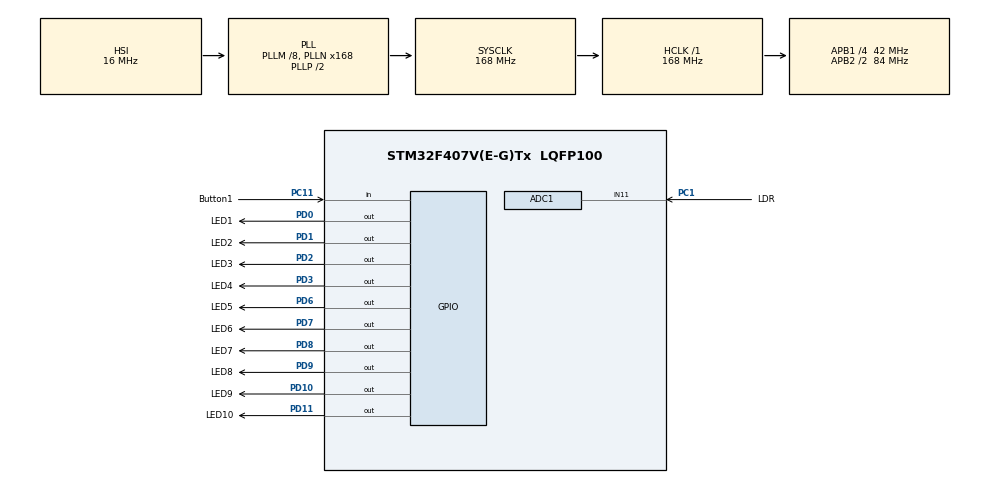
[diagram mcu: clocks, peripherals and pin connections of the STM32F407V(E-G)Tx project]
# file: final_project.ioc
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ADC1.Channel-0\#ChannelRegularConversion=ADC_CHANNEL_11
ADC1.ContinuousConvMode=ENABLE
ADC1.NbrOfConversionFlag=1
ADC1.Rank-0\#ChannelRegularConversion=1
ADC1.SamplingTime-0\#ChannelRegularConversion=ADC_SAMPLETIME_480CYCLES
ADC1.master=1
Mcu.Family=STM32F4
Mcu.Name=STM32F407V(E-G)Tx
Mcu.Package=LQFP100
NVIC.ADC_IRQn=true\:0\:0\:false\:false\:true\:true\:true\:true
NVIC.PriorityGroup=NVIC_PRIORITYGROUP_4
NVIC.TIM4_IRQn=true\:0\:0\:false\:false\:true\:true\:true\:true
PC1.GPIO_Label=LDR
PC1.Signal=ADCx_IN11
PC11.GPIO_Label=Button1
PC11.Signal=GPIO_Input
PD0.GPIO_Label=LED1
PD0.Signal=GPIO_Output
PD1.GPIO_Label=LED2
PD1.Signal=GPIO_Output
PD10.GPIO_Label=LED9
PD10.Signal=GPIO_Output
PD11.GPIO_Label=LED10
PD11.Signal=GPIO_Output
PD2.GPIO_Label=LED3
PD2.Signal=GPIO_Output
PD3.GPIO_Label=LED4
PD3.Signal=GPIO_Output
PD6.GPIO_Label=LED5
PD6.Signal=GPIO_Output
PD7.GPIO_Label=LED6
PD7.Signal=GPIO_Output
PD8.GPIO_Label=LED7
PD8.Signal=GPIO_Output
PD9.GPIO_Label=LED8
PD9.Signal=GPIO_Output
ProjectManager.HeapSize=0x200
ProjectManager.StackSize=0x400
ProjectManager.TargetToolchain=STM32CubeIDE
RCC.48MHZClocksFreq_Value=84000000
RCC.AHBFreq_Value=168000000
RCC.APB1CLKDivider=RCC_HCLK_DIV4
RCC.APB1Freq_Value=42000000
RCC.APB1TimFreq_Value=84000000
RCC.APB2CLKDivider=RCC_HCLK_DIV2
RCC.APB2Freq_Value=84000000
RCC.APB2TimFreq_Value=168000000
RCC.CortexFreq_Value=168000000
RCC.HCLKFreq_Value=168000000
RCC.HSE_VALUE=25000000
RCC.HSI_VALUE=16000000
RCC.LSE_VALUE=32768
RCC.PLLM=8
RCC.PLLN=168
RCC.SYSCLKFreq_VALUE=168000000
RCC.SYSCLKSource=RCC_SYSCLKSOURCE_PLLCLK
RCC.VCOOutputFreq_Value=336000000
SH.ADCx_IN11.0=ADC1_IN11,IN11
TIM4.Period=200
TIM4.Prescaler=42000-1
TIM9.Period=4096-1
TIM9.Prescaler=16800-1
VP_TIM4_VS_ClockSourceINT.Mode=Internal
VP_TIM9_VS_ClockSourceINT.Mode=Internal
board=custom

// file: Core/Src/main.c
/* USER CODE BEGIN Header */
/**
  ******************************************************************************
  * @file           : main.c
  * @brief          : Main program body
  ******************************************************************************
  * @attention
  *
  * Copyright (c) 2023 STMicroelectronics.
  * All rights reserved.
  *
  * This software is licensed under terms that can be found in the LICENSE file
  * in the root directory of this software component.
  * If no LICENSE file comes with this software, it is provided AS-IS.
  *
  ******************************************************************************
  */
/* USER CODE END Header */
#include "main.h"

/* USER CODE BEGIN Includes */

#include "arm_math.h"
arm_fir_instance_f32 myFilter;

//// CHECK SOFTWARE PACKS COMPONENT SELECTROR FOR FOR XCUBE ALGOBUILD - YOU WILL SEE DSP LIBRARY
//// ON THE IOC WINDOW YOU WILL SEE MIDDLEWARE - CHECK POSSIBILITIES

/* USER CODE END Includes */

ADC_HandleTypeDef hadc1;

TIM_HandleTypeDef htim4;
TIM_HandleTypeDef htim9;

void SystemClock_Config(void);
static void MX_GPIO_Init(void);
static void MX_ADC1_Init(void);
static void MX_TIM4_Init(void);
static void MX_TIM9_Init(void);

int main(void)
{

  /* MCU Configuration--------------------------------------------------------*/

  /* Reset of all peripherals, Initializes the Flash interface and the Systick. */
  HAL_Init();

  /* Configure the system clock */
  SystemClock_Config();

  /* Initialize all configured peripherals */
  MX_GPIO_Init();
  MX_ADC1_Init();
  MX_TIM4_Init();
  MX_TIM9_Init();

  /* Infinite loop */
  while (1)
  {

  }
}

void SystemClock_Config(void)
{
  RCC_OscInitTypeDef RCC_OscInitStruct = {0};
  RCC_ClkInitTypeDef RCC_ClkInitStruct = {0};

  /** Configure the main internal regulator output voltage
  */
  __HAL_RCC_PWR_CLK_ENABLE();
  __HAL_PWR_VOLTAGESCALING_CONFIG(PWR_REGULATOR_VOLTAGE_SCALE1);

  /** Initializes the RCC Oscillators according to the specified parameters
  * in the RCC_OscInitTypeDef structure.
  */
  RCC_OscInitStruct.OscillatorType = RCC_OSCILLATORTYPE_HSI;
  RCC_OscInitStruct.HSIState = RCC_HSI_ON;
  RCC_OscInitStruct.HSICalibrationValue = RCC_HSICALIBRATION_DEFAULT;
  RCC_OscInitStruct.PLL.PLLState = RCC_PLL_ON;
  RCC_OscInitStruct.PLL.PLLSource = RCC_PLLSOURCE_HSI;
  RCC_OscInitStruct.PLL.PLLM = 8;
  RCC_OscInitStruct.PLL.PLLN = 168;
  RCC_OscInitStruct.PLL.PLLP = RCC_PLLP_DIV2;
  RCC_OscInitStruct.PLL.PLLQ = 4;
  if (HAL_RCC_OscConfig(&RCC_OscInitStruct) != HAL_OK)
  {
    Error_Handler();
  }

  /** Initializes the CPU, AHB and APB buses clocks
  */
  RCC_ClkInitStruct.ClockType = RCC_CLOCKTYPE_HCLK|RCC_CLOCKTYPE_SYSCLK
                              |RCC_CLOCKTYPE_PCLK1|RCC_CLOCKTYPE_PCLK2;
  RCC_ClkInitStruct.SYSCLKSource = RCC_SYSCLKSOURCE_PLLCLK;
  RCC_ClkInitStruct.AHBCLKDivider = RCC_SYSCLK_DIV1;
  RCC_ClkInitStruct.APB1CLKDivider = RCC_HCLK_DIV4;
  RCC_ClkInitStruct.APB2CLKDivider = RCC_HCLK_DIV2;

  if (HAL_RCC_ClockConfig(&RCC_ClkInitStruct, FLASH_LATENCY_5) != HAL_OK)
  {
    Error_Handler();
  }
}

static void MX_ADC1_Init(void)
{

  ADC_ChannelConfTypeDef sConfig = {0};

  /** Configure the global features of the ADC (Clock, Resolution, Data Alignment and number of conversion)
  */
  hadc1.Instance = ADC1;
  hadc1.Init.ClockPrescaler = ADC_CLOCK_SYNC_PCLK_DIV4;
  hadc1.Init.Resolution = ADC_RESOLUTION_12B;
  hadc1.Init.ScanConvMode = DISABLE;
  hadc1.Init.ContinuousConvMode = ENABLE;
  hadc1.Init.DiscontinuousConvMode = DISABLE;
  hadc1.Init.ExternalTrigConvEdge = ADC_EXTERNALTRIGCONVEDGE_NONE;
  hadc1.Init.ExternalTrigConv = ADC_SOFTWARE_START;
  hadc1.Init.DataAlign = ADC_DATAALIGN_RIGHT;
  hadc1.Init.NbrOfConversion = 1;
  hadc1.Init.DMAContinuousRequests = DISABLE;
  hadc1.Init.EOCSelection = ADC_EOC_SINGLE_CONV;
  if (HAL_ADC_Init(&hadc1) != HAL_OK)
  {
    Error_Handler();
  }

  /** Configure for the selected ADC regular channel its corresponding rank in the sequencer and its sample time.
  */
  sConfig.Channel = ADC_CHANNEL_11;
  sConfig.Rank = 1;
  sConfig.SamplingTime = ADC_SAMPLETIME_480CYCLES;
  if (HAL_ADC_ConfigChannel(&hadc1, &sConfig) != HAL_OK)
  {
    Error_Handler();
  }

}

static void MX_TIM4_Init(void)
{

  TIM_ClockConfigTypeDef sClockSourceConfig = {0};
  TIM_MasterConfigTypeDef sMasterConfig = {0};

  htim4.Instance = TIM4;
  htim4.Init.Prescaler = 42000-1;
  htim4.Init.CounterMode = TIM_COUNTERMODE_UP;
  htim4.Init.Period = 200;
  htim4.Init.ClockDivision = TIM_CLOCKDIVISION_DIV1;
  htim4.Init.AutoReloadPreload = TIM_AUTORELOAD_PRELOAD_DISABLE;
  if (HAL_TIM_Base_Init(&htim4) != HAL_OK)
  {
    Error_Handler();
  }
  sClockSourceConfig.ClockSource = TIM_CLOCKSOURCE_INTERNAL;
  if (HAL_TIM_ConfigClockSource(&htim4, &sClockSourceConfig) != HAL_OK)
  {
    Error_Handler();
  }
  sMasterConfig.MasterOutputTrigger = TIM_TRGO_RESET;
  sMasterConfig.MasterSlaveMode = TIM_MASTERSLAVEMODE_DISABLE;
  if (HAL_TIMEx_MasterConfigSynchronization(&htim4, &sMasterConfig) != HAL_OK)
  {
    Error_Handler();
  }

}

static void MX_TIM9_Init(void)
{

  TIM_ClockConfigTypeDef sClockSourceConfig = {0};

  htim9.Instance = TIM9;
  htim9.Init.Prescaler = 16800-1;
  htim9.Init.CounterMode = TIM_COUNTERMODE_UP;
  htim9.Init.Period = 4096-1;
  htim9.Init.ClockDivision = TIM_CLOCKDIVISION_DIV1;
  htim9.Init.AutoReloadPreload = TIM_AUTORELOAD_PRELOAD_DISABLE;
  if (HAL_TIM_Base_Init(&htim9) != HAL_OK)
  {
    Error_Handler();
  }
  sClockSourceConfig.ClockSource = TIM_CLOCKSOURCE_INTERNAL;
  if (HAL_TIM_ConfigClockSource(&htim9, &sClockSourceConfig) != HAL_OK)
  {
    Error_Handler();
  }

}

static void MX_GPIO_Init(void)
{
  GPIO_InitTypeDef GPIO_InitStruct = {0};

  /* GPIO Ports Clock Enable */
  __HAL_RCC_GPIOC_CLK_ENABLE();
  __HAL_RCC_GPIOD_CLK_ENABLE();

  /*Configure GPIO pin Output Level */
  HAL_GPIO_WritePin(GPIOD, LED7_Pin|LED8_Pin|LED9_Pin|LED10_Pin
                          |LED1_Pin|LED2_Pin|LED3_Pin|LED4_Pin
                          |LED5_Pin|LED6_Pin, GPIO_PIN_RESET);

  /*Configure GPIO pins : LED7_Pin LED8_Pin LED9_Pin LED10_Pin
                           LED1_Pin LED2_Pin LED3_Pin LED4_Pin
                           LED5_Pin LED6_Pin */
  GPIO_InitStruct.Pin = LED7_Pin|LED8_Pin|LED9_Pin|LED10_Pin
                          |LED1_Pin|LED2_Pin|LED3_Pin|LED4_Pin
                          |LED5_Pin|LED6_Pin;
  GPIO_InitStruct.Mode = GPIO_MODE_OUTPUT_PP;
  GPIO_InitStruct.Pull = GPIO_NOPULL;
  GPIO_InitStruct.Speed = GPIO_SPEED_FREQ_LOW;
  HAL_GPIO_Init(GPIOD, &GPIO_InitStruct);

  /*Configure GPIO pin : Button1_Pin */
  GPIO_InitStruct.Pin = Button1_Pin;
  GPIO_InitStruct.Mode = GPIO_MODE_INPUT;
  GPIO_InitStruct.Pull = GPIO_NOPULL;
  HAL_GPIO_Init(Button1_GPIO_Port, &GPIO_InitStruct);

}

void Error_Handler(void)
{
  __disable_irq();
  while (1)
  {
  }
}
